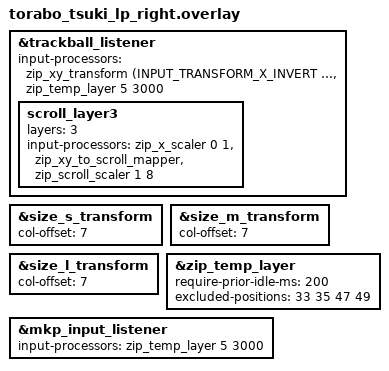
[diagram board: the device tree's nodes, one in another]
#include "torabo_tsuki_lp.dtsi"
#include <input/processors.dtsi>
#include <dt-bindings/zmk/input_transform.h>

&trackball_listener {
    /* 通常（カーソル移動）：XY反転のみ */
    /* input-processors = <&zip_xy_transform (INPUT_TRANSFORM_X_INVERT | INPUT_TRANSFORM_Y_INVERT)>; */
    input-processors = <
        &zip_xy_transform (INPUT_TRANSFORM_X_INVERT | INPUT_TRANSFORM_Y_INVERT)
        &zip_temp_layer 5 3000
    >;

    /* layer3：スクロールのみ（方向反転なし） */
    scroll_layer3 {
        layers = <3>;
        input-processors = <
            &zip_x_scaler 0 1
            &zip_xy_to_scroll_mapper
            &zip_scroll_scaler 1 8
        >;
    };
};

&size_s_transform {
    col-offset = <7>;
};

&size_m_transform {
    col-offset = <7>;
};

&size_l_transform {
    col-offset = <7>;
};

&zip_temp_layer {
    require-prior-idle-ms = <200>;
    excluded-positions = <33 35 47 49>;
};

&mkp_input_listener {
    input-processors = <&zip_temp_layer 5 3000>;
};
